VERSION ""

NS_ :

BS_:

BU_: VCU ECU

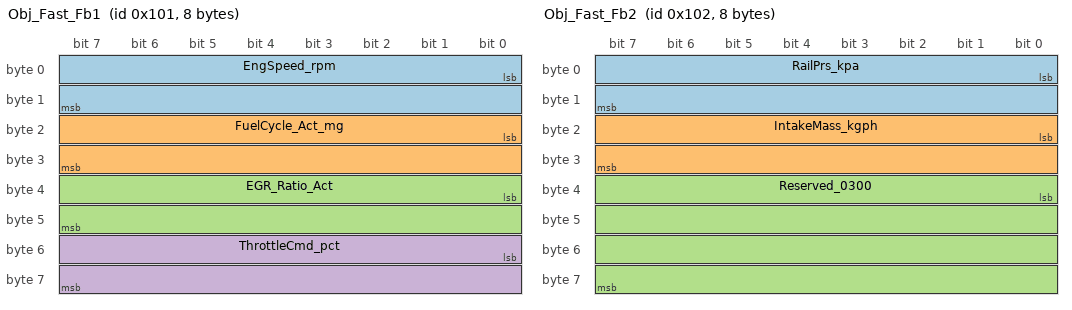
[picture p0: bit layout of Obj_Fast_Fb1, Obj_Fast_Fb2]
BO_ 257 Obj_Fast_Fb1: 8 ECU
 SG_ EngSpeed_rpm : 0|16@1+ (0.1,0) [0|3000] "rpm"  VCU
 SG_ FuelCycle_Act_mg : 16|16@1+ (0.005,0) [0|200] "mg/cycle"  VCU
 SG_ EGR_Ratio_Act : 32|16@1+ (0.001,0) [0|50] ""  VCU
 SG_ ThrottleCmd_pct : 48|16@1+ (0.01,0) [0|100] "%"  VCU

BO_ 258 Obj_Fast_Fb2: 8 ECU
 SG_ RailPrs_kpa : 0|16@1+ (5,0) [0|2000] "kPa"  VCU
 SG_ IntakeMass_kgph : 16|16@1+ (0.1,0) [0|1500] "kg/h"  VCU
 SG_ Reserved_0300 : 32|32@1+ (1,0) [0|4294967295] ""  VCU

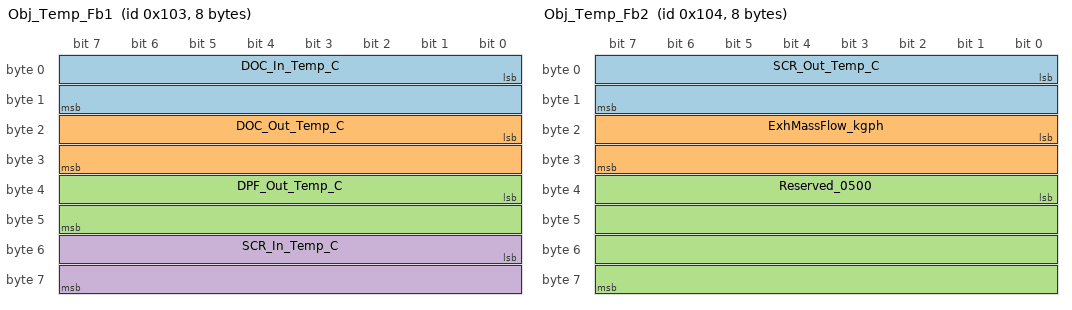
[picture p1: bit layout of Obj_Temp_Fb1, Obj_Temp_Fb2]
BO_ 259 Obj_Temp_Fb1: 8 ECU
 SG_ DOC_In_Temp_C : 0|16@1+ (0.1,0) [0|1000] "degC"  VCU
 SG_ DOC_Out_Temp_C : 16|16@1+ (0.1,0) [0|1000] "degC"  VCU
 SG_ DPF_Out_Temp_C : 32|16@1+ (0.1,0) [0|1000] "degC"  VCU
 SG_ SCR_In_Temp_C : 48|16@1+ (0.1,0) [0|1000] "degC"  VCU

BO_ 260 Obj_Temp_Fb2: 8 ECU
 SG_ SCR_Out_Temp_C : 0|16@1+ (0.1,0) [0|1000] "degC"  VCU
 SG_ ExhMassFlow_kgph : 16|16@1+ (0.1,0) [0|2000] "kg/h"  VCU
 SG_ Reserved_0500 : 32|32@1+ (1,0) [0|4294967295] ""  VCU

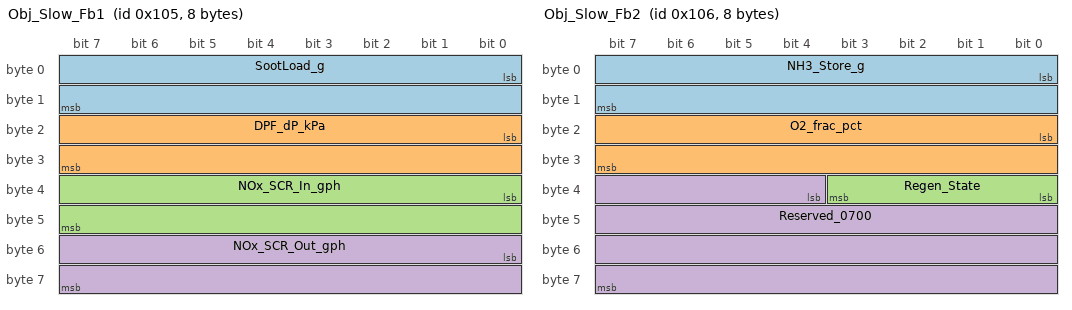
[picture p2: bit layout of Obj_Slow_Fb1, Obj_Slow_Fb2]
BO_ 261 Obj_Slow_Fb1: 8 ECU
 SG_ SootLoad_g : 0|16@1+ (0.01,0) [0|80] "g"  VCU
 SG_ DPF_dP_kPa : 16|16@1+ (0.01,0) [0|20] "kPa"  VCU
 SG_ NOx_SCR_In_gph : 32|16@1+ (0.1,0) [0|2000] "g/h"  VCU
 SG_ NOx_SCR_Out_gph : 48|16@1+ (0.1,0) [0|2000] "g/h"  VCU

BO_ 262 Obj_Slow_Fb2: 8 ECU
 SG_ NH3_Store_g : 0|16@1+ (0.01,0) [0|10] "g"  VCU
 SG_ O2_frac_pct : 16|16@1+ (0.01,0) [0|21] "%"  VCU
 SG_ Regen_State : 32|4@1+ (1,0) [0|15] ""  VCU
 SG_ Reserved_0700 : 36|28@1+ (1,0) [0|268435455] ""  VCU

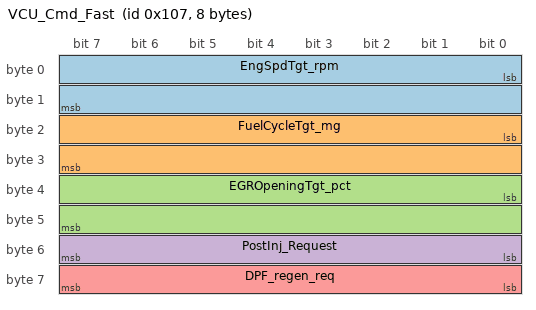
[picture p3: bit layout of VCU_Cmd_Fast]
BO_ 263 VCU_Cmd_Fast: 8 VCU
 SG_ EngSpdTgt_rpm : 0|16@1+ (0.1,0) [0|3000] "rpm"  ECU
 SG_ FuelCycleTgt_mg : 16|16@1+ (0.005,0) [0|200] "mg/cycle"  ECU
 SG_ EGROpeningTgt_pct : 32|16@1+ (0.01,0) [0|100] "%"  ECU
 SG_ PostInj_Request : 48|8@1+ (1,0) [0|1] ""  ECU
 SG_ DPF_regen_req : 56|8@1+ (1,0) [0|1] ""  ECU

BO_ 264 VCU_Cmd_Slow: 8 VCU
 SG_ mUREA_target_gph : 32|32@1- (0.1,0) [-3.4E+37|3.4E+37] "g/h"  ECU
 SG_ Reserved_0900 : 0|32@1- (1,0) [-3.4E+38|3.4E+38] ""  ECU

VAL_ 262 Regen_State 0 "Standby" 1 "WaitCondition" 2 "Regenerating" 3 "RegenProhibited" ;
VAL_ 263 PostInj_Request 1 "Request" ;
VAL_ 263 DPF_regen_req 1 "Request" ;
SIG_VALTYPE_ 264 mUREA_target_gph : 1;
SIG_VALTYPE_ 264 Reserved_0900 : 1;
